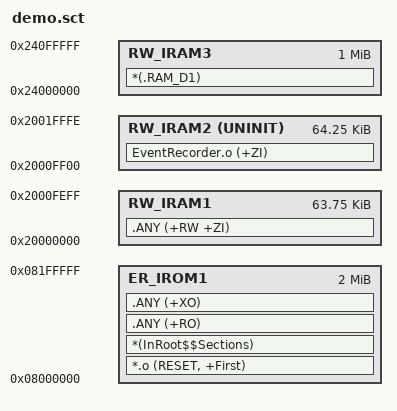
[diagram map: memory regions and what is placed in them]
; *************************************************************
; *** Scatter-Loading Description File generated by uVision ***
; *************************************************************

LR_IROM1 0x08000000 0x00200000  {    ; load region size_region
  ER_IROM1 0x08000000 0x00200000  {  ; load address = execution address
   *.o (RESET, +First)
   *(InRoot$$Sections)
   .ANY (+RO)
   .ANY (+XO)
  }
	RW_IRAM1 0x20000000 0x0000FF00 { ; RW data - 128KB DTCM
		.ANY (+RW +ZI)
	}
	
	RW_IRAM2 0x2000FF00 UNINIT 0x000100FF  {
		EventRecorder.o (+ZI) 
	}
	
	RW_IRAM3 0x24000000 0x000100000 { ; RW data - 512KB AXI SRAM
		*(.RAM_D1)
	}
}

